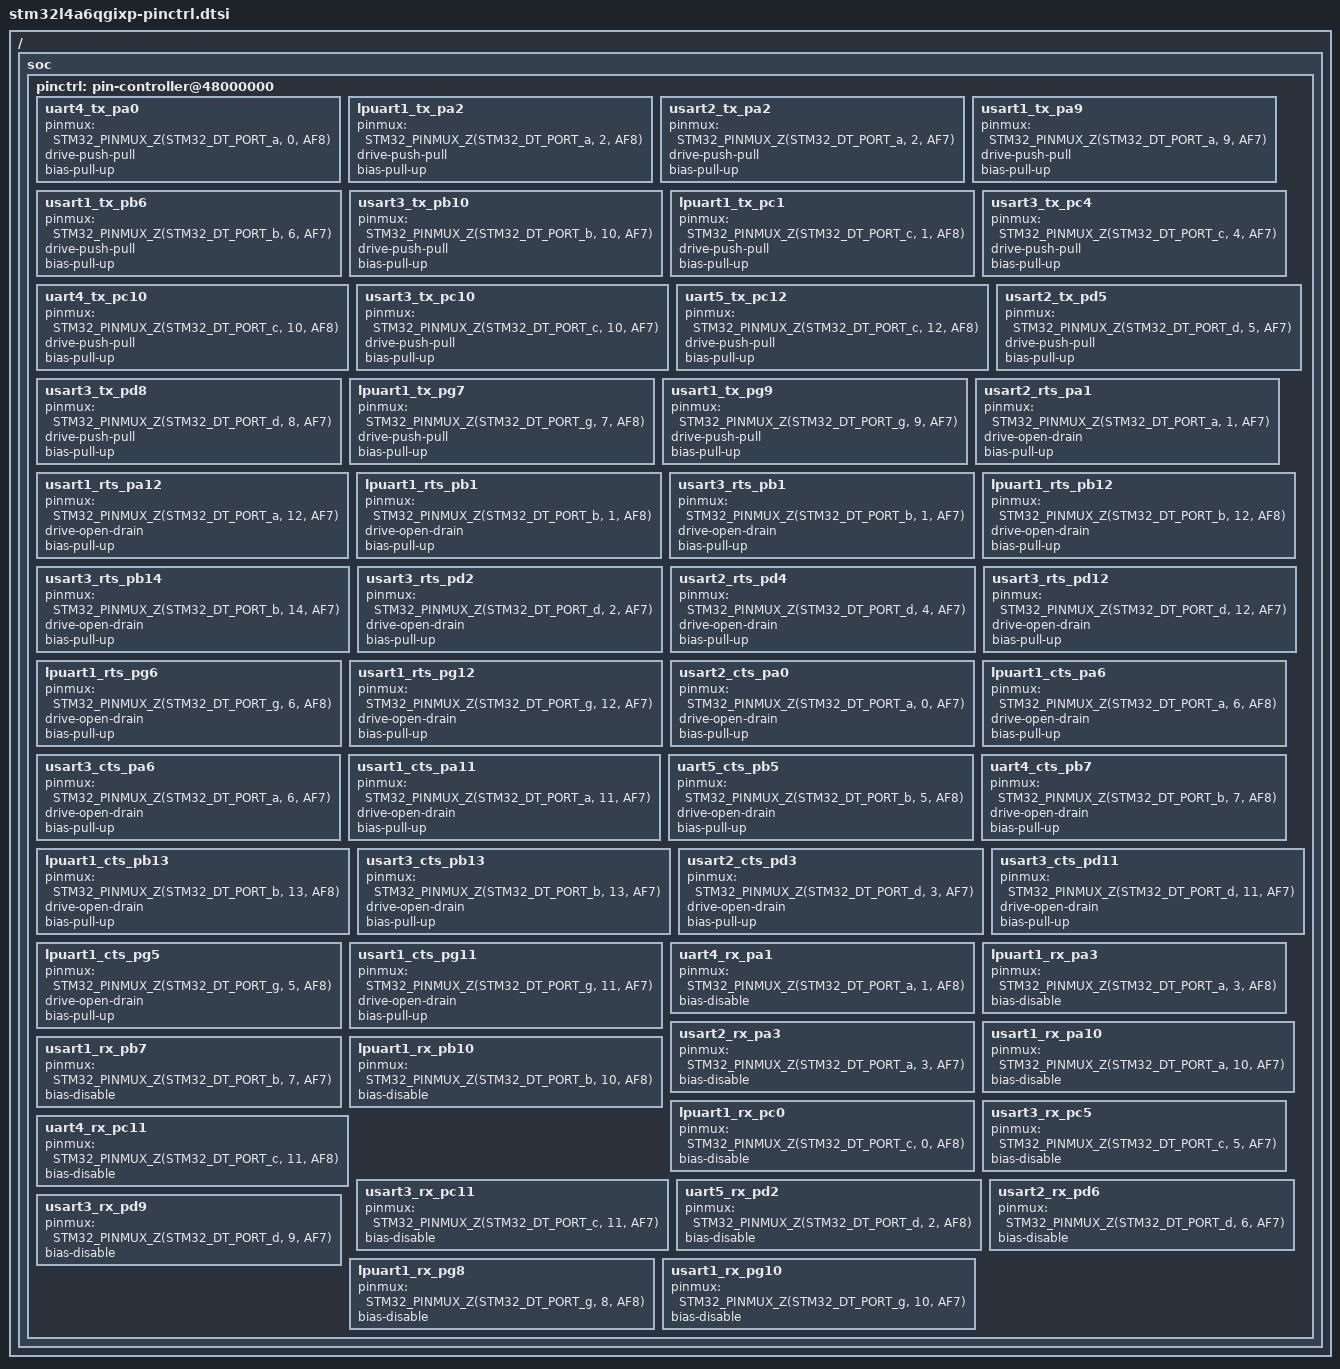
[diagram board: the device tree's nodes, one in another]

/*
 * NOTE: Autogenerated file using stm32_pinctrl_gen.py
 *
 * SPDX-License-Identifier: Apache-2.0
 */

#include <dt-bindings/pinctrl/stm32-pinctrl.h>

/ {
	soc {
		pinctrl: pin-controller@48000000 {
			/* UART_TX */
			uart4_tx_pa0: uart4_tx_pa0 {
				pinmux = <STM32_PINMUX_Z(STM32_DT_PORT_a, 0, AF8)>;
				drive-push-pull;
				bias-pull-up;
			};

			lpuart1_tx_pa2: lpuart1_tx_pa2 {
				pinmux = <STM32_PINMUX_Z(STM32_DT_PORT_a, 2, AF8)>;
				drive-push-pull;
				bias-pull-up;
			};

			lpuart1_tx_pa2: lpuart1_tx_pa2 {
				pinmux = <STM32_PINMUX_Z(STM32_DT_PORT_a, 2, AF8)>;
				drive-push-pull;
				bias-pull-up;
			};

			usart2_tx_pa2: usart2_tx_pa2 {
				pinmux = <STM32_PINMUX_Z(STM32_DT_PORT_a, 2, AF7)>;
				drive-push-pull;
				bias-pull-up;
			};

			usart1_tx_pa9: usart1_tx_pa9 {
				pinmux = <STM32_PINMUX_Z(STM32_DT_PORT_a, 9, AF7)>;
				drive-push-pull;
				bias-pull-up;
			};

			usart1_tx_pb6: usart1_tx_pb6 {
				pinmux = <STM32_PINMUX_Z(STM32_DT_PORT_b, 6, AF7)>;
				drive-push-pull;
				bias-pull-up;
			};

			usart3_tx_pb10: usart3_tx_pb10 {
				pinmux = <STM32_PINMUX_Z(STM32_DT_PORT_b, 10, AF7)>;
				drive-push-pull;
				bias-pull-up;
			};

			lpuart1_tx_pc1: lpuart1_tx_pc1 {
				pinmux = <STM32_PINMUX_Z(STM32_DT_PORT_c, 1, AF8)>;
				drive-push-pull;
				bias-pull-up;
			};

			lpuart1_tx_pc1: lpuart1_tx_pc1 {
				pinmux = <STM32_PINMUX_Z(STM32_DT_PORT_c, 1, AF8)>;
				drive-push-pull;
				bias-pull-up;
			};

			usart3_tx_pc4: usart3_tx_pc4 {
				pinmux = <STM32_PINMUX_Z(STM32_DT_PORT_c, 4, AF7)>;
				drive-push-pull;
				bias-pull-up;
			};

			uart4_tx_pc10: uart4_tx_pc10 {
				pinmux = <STM32_PINMUX_Z(STM32_DT_PORT_c, 10, AF8)>;
				drive-push-pull;
				bias-pull-up;
			};

			usart3_tx_pc10: usart3_tx_pc10 {
				pinmux = <STM32_PINMUX_Z(STM32_DT_PORT_c, 10, AF7)>;
				drive-push-pull;
				bias-pull-up;
			};

			uart5_tx_pc12: uart5_tx_pc12 {
				pinmux = <STM32_PINMUX_Z(STM32_DT_PORT_c, 12, AF8)>;
				drive-push-pull;
				bias-pull-up;
			};

			usart2_tx_pd5: usart2_tx_pd5 {
				pinmux = <STM32_PINMUX_Z(STM32_DT_PORT_d, 5, AF7)>;
				drive-push-pull;
				bias-pull-up;
			};

			usart3_tx_pd8: usart3_tx_pd8 {
				pinmux = <STM32_PINMUX_Z(STM32_DT_PORT_d, 8, AF7)>;
				drive-push-pull;
				bias-pull-up;
			};

			lpuart1_tx_pg7: lpuart1_tx_pg7 {
				pinmux = <STM32_PINMUX_Z(STM32_DT_PORT_g, 7, AF8)>;
				drive-push-pull;
				bias-pull-up;
			};

			lpuart1_tx_pg7: lpuart1_tx_pg7 {
				pinmux = <STM32_PINMUX_Z(STM32_DT_PORT_g, 7, AF8)>;
				drive-push-pull;
				bias-pull-up;
			};

			usart1_tx_pg9: usart1_tx_pg9 {
				pinmux = <STM32_PINMUX_Z(STM32_DT_PORT_g, 9, AF7)>;
				drive-push-pull;
				bias-pull-up;
			};


			/* UART_RTS */
			usart2_rts_pa1: usart2_rts_pa1 {
				pinmux = <STM32_PINMUX_Z(STM32_DT_PORT_a, 1, AF7)>;
				drive-open-drain;
				bias-pull-up;
			};

			usart1_rts_pa12: usart1_rts_pa12 {
				pinmux = <STM32_PINMUX_Z(STM32_DT_PORT_a, 12, AF7)>;
				drive-open-drain;
				bias-pull-up;
			};

			lpuart1_rts_pb1: lpuart1_rts_pb1 {
				pinmux = <STM32_PINMUX_Z(STM32_DT_PORT_b, 1, AF8)>;
				drive-open-drain;
				bias-pull-up;
			};

			lpuart1_rts_pb1: lpuart1_rts_pb1 {
				pinmux = <STM32_PINMUX_Z(STM32_DT_PORT_b, 1, AF8)>;
				drive-open-drain;
				bias-pull-up;
			};

			usart3_rts_pb1: usart3_rts_pb1 {
				pinmux = <STM32_PINMUX_Z(STM32_DT_PORT_b, 1, AF7)>;
				drive-open-drain;
				bias-pull-up;
			};

			lpuart1_rts_pb12: lpuart1_rts_pb12 {
				pinmux = <STM32_PINMUX_Z(STM32_DT_PORT_b, 12, AF8)>;
				drive-open-drain;
				bias-pull-up;
			};

			lpuart1_rts_pb12: lpuart1_rts_pb12 {
				pinmux = <STM32_PINMUX_Z(STM32_DT_PORT_b, 12, AF8)>;
				drive-open-drain;
				bias-pull-up;
			};

			usart3_rts_pb14: usart3_rts_pb14 {
				pinmux = <STM32_PINMUX_Z(STM32_DT_PORT_b, 14, AF7)>;
				drive-open-drain;
				bias-pull-up;
			};

			usart3_rts_pd2: usart3_rts_pd2 {
				pinmux = <STM32_PINMUX_Z(STM32_DT_PORT_d, 2, AF7)>;
				drive-open-drain;
				bias-pull-up;
			};

			usart2_rts_pd4: usart2_rts_pd4 {
				pinmux = <STM32_PINMUX_Z(STM32_DT_PORT_d, 4, AF7)>;
				drive-open-drain;
				bias-pull-up;
			};

			usart3_rts_pd12: usart3_rts_pd12 {
				pinmux = <STM32_PINMUX_Z(STM32_DT_PORT_d, 12, AF7)>;
				drive-open-drain;
				bias-pull-up;
			};

			lpuart1_rts_pg6: lpuart1_rts_pg6 {
				pinmux = <STM32_PINMUX_Z(STM32_DT_PORT_g, 6, AF8)>;
				drive-open-drain;
				bias-pull-up;
			};

			lpuart1_rts_pg6: lpuart1_rts_pg6 {
				pinmux = <STM32_PINMUX_Z(STM32_DT_PORT_g, 6, AF8)>;
				drive-open-drain;
				bias-pull-up;
			};

			usart1_rts_pg12: usart1_rts_pg12 {
				pinmux = <STM32_PINMUX_Z(STM32_DT_PORT_g, 12, AF7)>;
				drive-open-drain;
				bias-pull-up;
			};


			/* UART_CTS */
			usart2_cts_pa0: usart2_cts_pa0 {
				pinmux = <STM32_PINMUX_Z(STM32_DT_PORT_a, 0, AF7)>;
				drive-open-drain;
				bias-pull-up;
			};

			lpuart1_cts_pa6: lpuart1_cts_pa6 {
				pinmux = <STM32_PINMUX_Z(STM32_DT_PORT_a, 6, AF8)>;
				drive-open-drain;
				bias-pull-up;
			};

			lpuart1_cts_pa6: lpuart1_cts_pa6 {
				pinmux = <STM32_PINMUX_Z(STM32_DT_PORT_a, 6, AF8)>;
				drive-open-drain;
				bias-pull-up;
			};

			usart3_cts_pa6: usart3_cts_pa6 {
				pinmux = <STM32_PINMUX_Z(STM32_DT_PORT_a, 6, AF7)>;
				drive-open-drain;
				bias-pull-up;
			};

			usart1_cts_pa11: usart1_cts_pa11 {
				pinmux = <STM32_PINMUX_Z(STM32_DT_PORT_a, 11, AF7)>;
				drive-open-drain;
				bias-pull-up;
			};

			uart5_cts_pb5: uart5_cts_pb5 {
				pinmux = <STM32_PINMUX_Z(STM32_DT_PORT_b, 5, AF8)>;
				drive-open-drain;
				bias-pull-up;
			};

			uart4_cts_pb7: uart4_cts_pb7 {
				pinmux = <STM32_PINMUX_Z(STM32_DT_PORT_b, 7, AF8)>;
				drive-open-drain;
				bias-pull-up;
			};

			lpuart1_cts_pb13: lpuart1_cts_pb13 {
				pinmux = <STM32_PINMUX_Z(STM32_DT_PORT_b, 13, AF8)>;
				drive-open-drain;
				bias-pull-up;
			};

			lpuart1_cts_pb13: lpuart1_cts_pb13 {
				pinmux = <STM32_PINMUX_Z(STM32_DT_PORT_b, 13, AF8)>;
				drive-open-drain;
				bias-pull-up;
			};

			usart3_cts_pb13: usart3_cts_pb13 {
				pinmux = <STM32_PINMUX_Z(STM32_DT_PORT_b, 13, AF7)>;
				drive-open-drain;
				bias-pull-up;
			};

			usart2_cts_pd3: usart2_cts_pd3 {
				pinmux = <STM32_PINMUX_Z(STM32_DT_PORT_d, 3, AF7)>;
				drive-open-drain;
				bias-pull-up;
			};

			usart3_cts_pd11: usart3_cts_pd11 {
				pinmux = <STM32_PINMUX_Z(STM32_DT_PORT_d, 11, AF7)>;
				drive-open-drain;
				bias-pull-up;
			};

			lpuart1_cts_pg5: lpuart1_cts_pg5 {
				pinmux = <STM32_PINMUX_Z(STM32_DT_PORT_g, 5, AF8)>;
				drive-open-drain;
				bias-pull-up;
			};

			lpuart1_cts_pg5: lpuart1_cts_pg5 {
				pinmux = <STM32_PINMUX_Z(STM32_DT_PORT_g, 5, AF8)>;
				drive-open-drain;
				bias-pull-up;
			};

			usart1_cts_pg11: usart1_cts_pg11 {
				pinmux = <STM32_PINMUX_Z(STM32_DT_PORT_g, 11, AF7)>;
				drive-open-drain;
				bias-pull-up;
			};


			/* UART_RX */
			uart4_rx_pa1: uart4_rx_pa1 {
				pinmux = <STM32_PINMUX_Z(STM32_DT_PORT_a, 1, AF8)>;
				bias-disable;
			};

			lpuart1_rx_pa3: lpuart1_rx_pa3 {
				pinmux = <STM32_PINMUX_Z(STM32_DT_PORT_a, 3, AF8)>;
				bias-disable;
			};

			lpuart1_rx_pa3: lpuart1_rx_pa3 {
				pinmux = <STM32_PINMUX_Z(STM32_DT_PORT_a, 3, AF8)>;
				bias-disable;
			};

			usart2_rx_pa3: usart2_rx_pa3 {
				pinmux = <STM32_PINMUX_Z(STM32_DT_PORT_a, 3, AF7)>;
				bias-disable;
			};

			usart1_rx_pa10: usart1_rx_pa10 {
				pinmux = <STM32_PINMUX_Z(STM32_DT_PORT_a, 10, AF7)>;
				bias-disable;
			};

			usart1_rx_pb7: usart1_rx_pb7 {
				pinmux = <STM32_PINMUX_Z(STM32_DT_PORT_b, 7, AF7)>;
				bias-disable;
			};

			lpuart1_rx_pb10: lpuart1_rx_pb10 {
				pinmux = <STM32_PINMUX_Z(STM32_DT_PORT_b, 10, AF8)>;
				bias-disable;
			};

			lpuart1_rx_pb10: lpuart1_rx_pb10 {
				pinmux = <STM32_PINMUX_Z(STM32_DT_PORT_b, 10, AF8)>;
				bias-disable;
			};

			lpuart1_rx_pc0: lpuart1_rx_pc0 {
				pinmux = <STM32_PINMUX_Z(STM32_DT_PORT_c, 0, AF8)>;
				bias-disable;
			};

			lpuart1_rx_pc0: lpuart1_rx_pc0 {
				pinmux = <STM32_PINMUX_Z(STM32_DT_PORT_c, 0, AF8)>;
				bias-disable;
			};

			usart3_rx_pc5: usart3_rx_pc5 {
				pinmux = <STM32_PINMUX_Z(STM32_DT_PORT_c, 5, AF7)>;
				bias-disable;
			};

			uart4_rx_pc11: uart4_rx_pc11 {
				pinmux = <STM32_PINMUX_Z(STM32_DT_PORT_c, 11, AF8)>;
				bias-disable;
			};

			usart3_rx_pc11: usart3_rx_pc11 {
				pinmux = <STM32_PINMUX_Z(STM32_DT_PORT_c, 11, AF7)>;
				bias-disable;
			};

			uart5_rx_pd2: uart5_rx_pd2 {
				pinmux = <STM32_PINMUX_Z(STM32_DT_PORT_d, 2, AF8)>;
				bias-disable;
			};

			usart2_rx_pd6: usart2_rx_pd6 {
				pinmux = <STM32_PINMUX_Z(STM32_DT_PORT_d, 6, AF7)>;
				bias-disable;
			};

			usart3_rx_pd9: usart3_rx_pd9 {
				pinmux = <STM32_PINMUX_Z(STM32_DT_PORT_d, 9, AF7)>;
				bias-disable;
			};

			lpuart1_rx_pg8: lpuart1_rx_pg8 {
				pinmux = <STM32_PINMUX_Z(STM32_DT_PORT_g, 8, AF8)>;
				bias-disable;
			};

			lpuart1_rx_pg8: lpuart1_rx_pg8 {
				pinmux = <STM32_PINMUX_Z(STM32_DT_PORT_g, 8, AF8)>;
				bias-disable;
			};

			usart1_rx_pg10: usart1_rx_pg10 {
				pinmux = <STM32_PINMUX_Z(STM32_DT_PORT_g, 10, AF7)>;
				bias-disable;
			};

		};
	};
};
